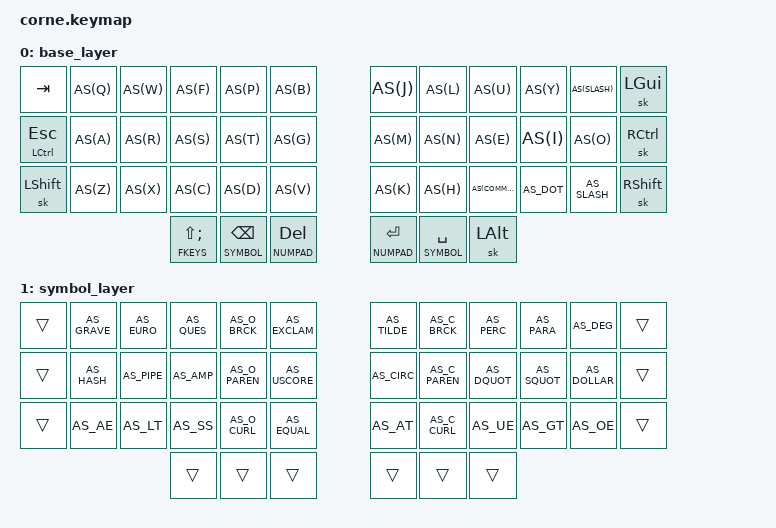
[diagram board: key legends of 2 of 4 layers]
/*
 * Copyright (c) 2020 The ZMK Contributors
 *
 * SPDX-License-Identifier: MIT
 */

#include <behaviors.dtsi>
#include <dt-bindings/zmk/keys.h>
#include <dt-bindings/zmk/bt.h>

#include "custom_behaviors.keymap"

#define BASE   0
#define SYMBOL 1
#define NUMPAD 2
#define FKEYS  3

// repeat consumer page keys in addition to hid keys
&key_repeat {
    usage-pages = <HID_USAGE_KEY HID_USAGE_CONSUMER>;
};

&sk {
    release-after-ms = <500>;
};

&mt {
    tapping-term-ms = <200>;
};

// the keymap requires the os to be set to de_DE
/ {
  keymap {
    compatible = "zmk,keymap";

    base_layer {
      // --------------------------------------------------------------------
      // | TAB       | Q | W | F | P | B |  | J | L | U | Y | - | OSM(GUI)  |
      // | CTRL(ESC) | A | R | S | T | G |  | M | N | E | I | O | OSM(Ctrl) |
      // | OSM(SHFT) | Z | X | C | D | V |  | K | H | . | , | / | OSM(SHFT) |
      //
      // | LT3(:) | LT1(Bksp) | LT2(Del) | -- | Lt2(Ret)| Lt1(Space)  | OSM(ALT) |
      bindings = <
        &kp TAB       AS(Q) AS(W) AS(F) AS(P) AS(B) AS(J) AS(L) AS(U)     AS(Y)  AS(SLASH) &sk LGUI
        &mt LCTRL ESC AS(A) AS(R) AS(S) AS(T) AS(G) AS(M) AS(N) AS(E)     AS(I)  AS(O)     &sk RCTRL
        &sk LSHFT     AS(Z) AS(X) AS(C) AS(D) AS(V) AS(K) AS(H) AS(COMMA) AS_DOT AS_SLASH  &sk RSHFT
        &lt FKEYS LS(SEMICOLON) &lt SYMBOL BACKSPACE &lt NUMPAD DELETE &lt NUMPAD ENTER &lt SYMBOL SPACE &sk LALT
        >;
    };

    symbol_layer {
      // -------------------------------------------------------------
      // | trans | ´ | € | ? | [ | ! |   | ~ | ] | % | § | ° | trans |
      // | trans | # | | | & | ( | _ |   | ^ | ) | " | ' | $ | trans |
      // | trans | Ä | < | ß | { | = |   | @ | } | Ü | > | Ö | trans |
      //
      // | trans | trans | trans | -- | trans trans  | trans 
      bindings = <
        &trans AS_GRAVE AS_EURO AS_QUES AS_O_BRCK  AS_EXCLAM AS_TILDE AS_C_BRCK  AS_PERC  AS_PARA  AS_DEG    &trans
        &trans AS_HASH  AS_PIPE AS_AMP  AS_O_PAREN AS_USCORE AS_CIRC  AS_C_PAREN AS_DQUOT AS_SQUOT AS_DOLLAR &trans
        &trans AS_AE    AS_LT   AS_SS   AS_O_CURL  AS_EQUAL  AS_AT    AS_C_CURL  AS_UE    AS_GT    AS_OE     &trans
        &trans &trans &trans &trans &trans &trans
        >;
    };

    numpad_layer {
      // ---------------------------------------------------------------------------------
      // | trans | PGUP  | MLEFT    | UP   | MRIGHT | MUP  |   | / | 7 | 8 | 9 | -  | trans |
      // | trans | PGDWN | LEFT     | DOWN | RIGHT  | MDWN |   | * | 4 | 5 | 6 | += | trans |
      // | trans | END   | OSM(C|G) | HYP  | MEH    | HOME |   | . | 1 | 2 | 3 | 0  | trans |
      //
      // | trans | trans | trans | -- | trans trans  | trans 
      bindings = <
        &trans &kp PAGE_UP   &none          &kp UP                &none             &none    &kp KP_SLASH    &kp NUMBER_7       &kp NUMBER_8      &kp NUMBER_9       &kp KP_SLASH &trans
        &trans &kp PAGE_DOWN &kp LEFT       &kp DOWN              &kp RIGHT         &none    &kp KP_MULTIPLY &mt LCTRL NUMBER_4 &mt LALT NUMBER_5 &mt LSHFT NUMBER_6 AS_PLUS_EQ   &trans
        &trans &kp END       &sk LG(LCTRL)  &sk LG(LC(LA(LSHFT))) &sk LC(LA(LSHFT)) &kp HOME AS_DOT_COMMA    &kp NUMBER_1       &kp NUMBER_2      &kp NUMBER_3       &kp NUMBER_0 &trans
        &trans &trans &trans &trans &trans &trans
        >;
    };

    fkey_layer {
      // -----------------------------------------------------------------------------------------
      // | PRINT |           |           | MA_N_BIL |           | NEXT |   | VOL_UP     | TD_F1 | TD_F2  | TD_F3  | TD_F4  | NAMES |
      // | SCLCK | MA_N_WORD | MA_N_LINE | MA_N_CL  | MA_N_BIF  | MUTE |   | PLAY_PAUSE | TD_F5 | TD_F6  | TD_F7  | TD_F8  | trans |
      // | BREAK |           |           |          | MA_D_LINE | PREV |   | VOL_DOWN   | TD_F9 | TD_F10 | TD_F11 | TD_F12 | trans |
      //
      // | trans |   |   | --  | POWER | SLEEP | trans |
      bindings = <
        &TD_PRINT_BT_NXT &none      &none      &MA_N_BIL &none     &kp C_NEXT &kp C_VOL_UP     &TD_F1 &TD_F2  &TD_F3 &TD_F4  &CU_NAMES
        &TD_SLCK_BT_PRV  &MA_N_WORD &MA_N_LINE &MA_N_CL  &MA_N_BIF &kp C_MUTE &kp C_PLAY_PAUSE &TD_F5 &TD_F6  &TD_F7  &TD_F8 &trans
        &trans &none &kp C_RESET &kp C_POWER &kp C_SLEEP &trans
        >;
    };
  };
};

// vim :set expandtab :textwidth=320 :set commentstring=//\ %s
